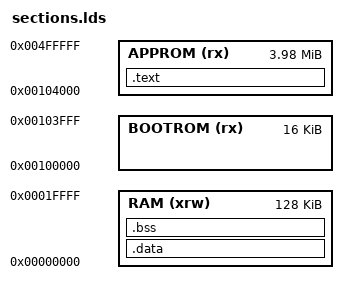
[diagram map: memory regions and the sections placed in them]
MEMORY
{
    BOOTROM (rx) : ORIGIN = 0x00100000, LENGTH = 0x004000
    APPROM (rx) : ORIGIN = 0x00104000, LENGTH = 0x3fc000
    RAM (xrw) : ORIGIN = 0x00000000, LENGTH = 0x20000
}

__bootrom_start__ = ORIGIN(BOOTROM);
__bootrom_size__ = LENGTH(BOOTROM);
__approm_start__ = ORIGIN(APPROM);
__approm_size__ = LENGTH(APPROM);

SECTIONS {
    .text :
    {
        . = ALIGN(4);
        *(.text)
        *(.text*)
        *(.rodata)
        *(.rodata*)
        *(.srodata)
        *(.srodata*)
        . = ALIGN(4);
        _etext = .;
        _sidata = _etext;
    } >APPROM
    .data : AT ( _sidata )
    {
        . = ALIGN(4);
        _sdata = .;
        _ram_start = .;
        . = ALIGN(4);
        *(.data)
        *(.data*)
        *(.sdata)
        *(.sdata*)
        . = ALIGN(4);
        _edata = .;
    } >RAM
    .bss :
    {
        . = ALIGN(4);
        _sbss = .;
        *(.bss)
        *(.bss*)
        *(.sbss)
        *(.sbss*)
        *(COMMON)
        . = ALIGN(4);
        _ebss = .;
    } >RAM
}
